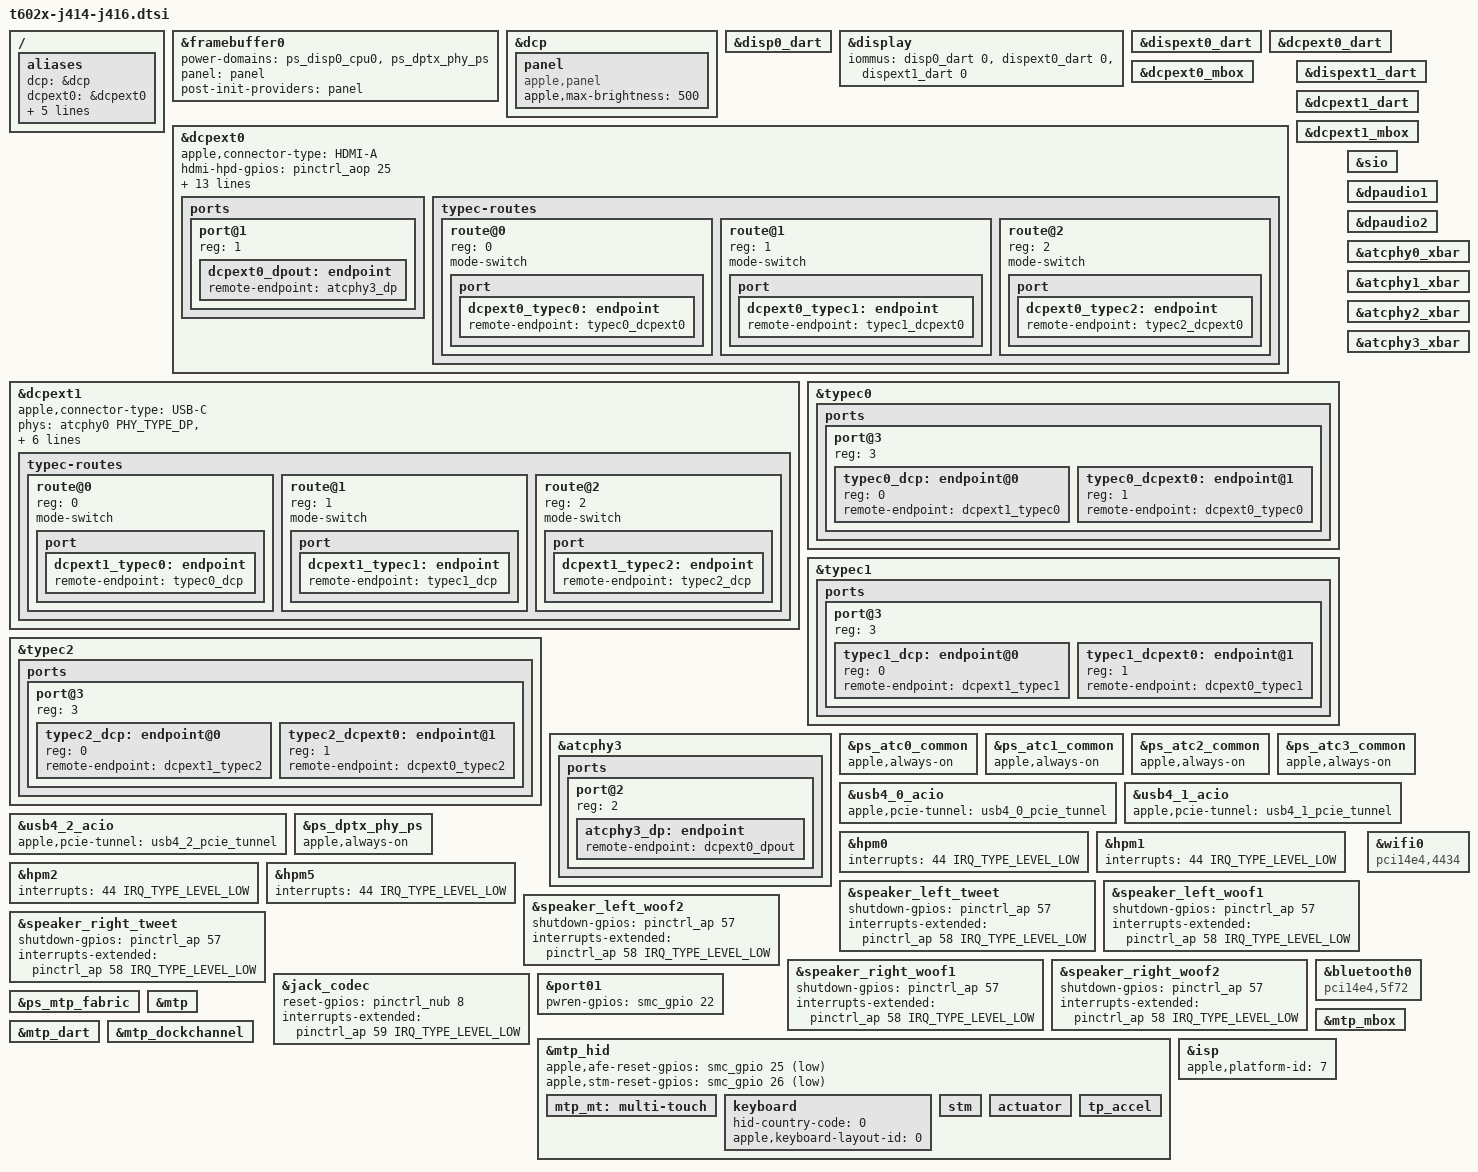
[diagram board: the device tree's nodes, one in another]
// SPDX-License-Identifier: GPL-2.0+ OR MIT
/*
 * MacBook Pro (14/16-inch, 2022)
 *
 * This file contains the parts common to J414 and J416 devices with both t6020 and t6021.
 *
 * target-type: J414s / J414c / J416s / J416c
 *
 * Copyright The Asahi Linux Contributors
 */

/*
 * These models are essentially identical to the previous generation, other than
 * the GPIO indices.
 */

#define NO_SPI_TRACKPAD
#include "t600x-j314-j316.dtsi"

/ {
	aliases {
		dcp = &dcp;
		dcpext0 = &dcpext0;
		dcpext1 = &dcpext1;
		disp0 = &display;
		disp0_piodma = &disp0_piodma;
		keyboard = &keyboard;
		sio = &sio;
	};
};

&framebuffer0 {
	power-domains = <&ps_disp0_cpu0>, <&ps_dptx_phy_ps>;
	panel = <&panel>;
	post-init-providers = <&panel>;
};

&dcp {
	panel: panel {
		compatible = "apple,panel";
		apple,max-brightness = <500>;
	};
};

&disp0_dart {
	status = "okay";
};

&display {
	iommus = <&disp0_dart 0>, <&dispext0_dart 0>, <&dispext1_dart 0>;
};

&dispext0_dart {
	status = "okay";
};

&dcpext0_dart {
	status = "okay";
};

&dcpext0_mbox {
	status = "okay";
};

&dcpext0 {
	status = "okay";
	apple,connector-type = "HDMI-A";
	hdmi-hpd-gpios = <&pinctrl_aop 25 GPIO_ACTIVE_HIGH>;
	hdmi-pwren-gpios = <&smc_gpio 23 GPIO_ACTIVE_HIGH>;
	dp2hdmi-pwren-gpios = <&smc_gpio 6 GPIO_ACTIVE_HIGH>;
	phys = <&atcphy3 PHY_TYPE_DP>, <&atcphy0 PHY_TYPE_DP>,
	       <&atcphy1 PHY_TYPE_DP>, <&atcphy2 PHY_TYPE_DP>;
	phy-names = "dp-phy", "typec0", "typec1", "typec2";
	mux-controls = <&atcphy3_xbar 0>, <&atcphy0_xbar 0>,
		       <&atcphy1_xbar 0>, <&atcphy2_xbar 0>;
	mux-control-names = "dp-xbar", "typec0", "typec1", "typec2";
	mux-index = <0>;
	apple,dptx-phy = <3>;
	apple,typec-mux-indices = <0 0 0>;
	apple,typec-dptx-phys = <0 1 2>;

	ports {
		#address-cells = <1>;
		#size-cells = <0>;

		port@1 {
			reg = <1>;
			dcpext0_dpout: endpoint {
				remote-endpoint = <&atcphy3_dp>;
			};
		};
	};

	typec-routes {
		#address-cells = <1>;
		#size-cells = <0>;

		route@0 {
			reg = <0>;
			mode-switch;

			port {
				dcpext0_typec0: endpoint {
					remote-endpoint = <&typec0_dcpext0>;
				};
			};
		};

		route@1 {
			reg = <1>;
			mode-switch;

			port {
				dcpext0_typec1: endpoint {
					remote-endpoint = <&typec1_dcpext0>;
				};
			};
		};

		route@2 {
			reg = <2>;
			mode-switch;

			port {
				dcpext0_typec2: endpoint {
					remote-endpoint = <&typec2_dcpext0>;
				};
			};
		};
	};
};

&dispext1_dart {
	status = "okay";
};

&dcpext1_dart {
	status = "okay";
};

&dcpext1_mbox {
	status = "okay";
};

&dcpext1 {
	/delete-property/ mux-index;
	status = "okay";
	apple,connector-type = "USB-C";
	phys = <&atcphy0 PHY_TYPE_DP>, <&atcphy1 PHY_TYPE_DP>,
	       <&atcphy2 PHY_TYPE_DP>;
	phy-names = "typec0", "typec1", "typec2";
	mux-controls = <&atcphy0_xbar 0>, <&atcphy1_xbar 0>,
		       <&atcphy2_xbar 0>;
	mux-control-names = "typec0", "typec1", "typec2";
	apple,typec-mux-indices = <2 2 2>;
	apple,typec-dptx-phys = <0 1 2>;

	typec-routes {
		#address-cells = <1>;
		#size-cells = <0>;

		route@0 {
			reg = <0>;
			mode-switch;

			port {
				dcpext1_typec0: endpoint {
					remote-endpoint = <&typec0_dcp>;
				};
			};
		};

		route@1 {
			reg = <1>;
			mode-switch;

			port {
				dcpext1_typec1: endpoint {
					remote-endpoint = <&typec1_dcp>;
				};
			};
		};

		route@2 {
			reg = <2>;
			mode-switch;

			port {
				dcpext1_typec2: endpoint {
					remote-endpoint = <&typec2_dcp>;
				};
			};
		};
	};
};

&typec0 {
	ports {
		port@3 {
			reg = <3>;
			#address-cells = <1>;
			#size-cells = <0>;

			typec0_dcp: endpoint@0 {
				reg = <0>;
				remote-endpoint = <&dcpext1_typec0>;
			};

			typec0_dcpext0: endpoint@1 {
				reg = <1>;
				remote-endpoint = <&dcpext0_typec0>;
			};
		};
	};
};

&typec1 {
	/delete-property/ displayport;
	ports {
		port@3 {
			reg = <3>;
			#address-cells = <1>;
			#size-cells = <0>;

			typec1_dcp: endpoint@0 {
				reg = <0>;
				remote-endpoint = <&dcpext1_typec1>;
			};

			typec1_dcpext0: endpoint@1 {
				reg = <1>;
				remote-endpoint = <&dcpext0_typec1>;
			};
		};
	};
};

&typec2 {
	ports {
		port@3 {
			reg = <3>;
			#address-cells = <1>;
			#size-cells = <0>;

			typec2_dcp: endpoint@0 {
				reg = <0>;
				remote-endpoint = <&dcpext1_typec2>;
			};

			typec2_dcpext0: endpoint@1 {
				reg = <1>;
				remote-endpoint = <&dcpext0_typec2>;
			};
		};
	};
};

&sio {
	status = "okay";
};

&dpaudio1 {
	status = "okay";
};

&dpaudio2 {
	status = "okay";
};

&atcphy0_xbar {
	status = "okay";
};

&atcphy1_xbar {
	status = "okay";
};

&atcphy2_xbar {
	status = "okay";
};

&atcphy3_xbar {
	status = "okay";
};

&atcphy3 {
	status = "okay";

	ports {
		#address-cells = <1>;
		#size-cells = <0>;

		port@2 {
			reg = <2>;
			atcphy3_dp: endpoint {
				remote-endpoint = <&dcpext0_dpout>;
			};
		};
	};
};

&ps_atc0_common {
	apple,always-on;
};

&ps_atc1_common {
	apple,always-on;
};

&ps_atc2_common {
	apple,always-on;
};

&ps_atc3_common {
	apple,always-on;
};

&usb4_0_acio {
	apple,pcie-tunnel = <&usb4_0_pcie_tunnel>;
};

&usb4_1_acio {
	apple,pcie-tunnel = <&usb4_1_pcie_tunnel>;
};

&usb4_2_acio {
	apple,pcie-tunnel = <&usb4_2_pcie_tunnel>;
};

/* Keep dptx_phy_ps on until DCP can sequence it during display bring-up. */
&ps_dptx_phy_ps {
	apple,always-on;
};

&dcpext0 {
	/*  HDMI HPD gpio, used as interrupt*/
	hdmi-hpd-gpios = <&pinctrl_aop 25 GPIO_ACTIVE_HIGH>;
};

&hpm0 {
	interrupts = <44 IRQ_TYPE_LEVEL_LOW>;
};

&hpm1 {
	interrupts = <44 IRQ_TYPE_LEVEL_LOW>;
};

&hpm2 {
	interrupts = <44 IRQ_TYPE_LEVEL_LOW>;
};

&hpm5 {
	interrupts = <44 IRQ_TYPE_LEVEL_LOW>;
};

&speaker_left_tweet {
	shutdown-gpios = <&pinctrl_ap 57 GPIO_ACTIVE_HIGH>;
	interrupts-extended = <&pinctrl_ap 58 IRQ_TYPE_LEVEL_LOW>;
};

&speaker_left_woof1 {
	shutdown-gpios = <&pinctrl_ap 57 GPIO_ACTIVE_HIGH>;
	interrupts-extended = <&pinctrl_ap 58 IRQ_TYPE_LEVEL_LOW>;
};

&speaker_left_woof2 {
	shutdown-gpios = <&pinctrl_ap 57 GPIO_ACTIVE_HIGH>;
	interrupts-extended = <&pinctrl_ap 58 IRQ_TYPE_LEVEL_LOW>;
};

&speaker_right_tweet {
	shutdown-gpios = <&pinctrl_ap 57 GPIO_ACTIVE_HIGH>;
	interrupts-extended = <&pinctrl_ap 58 IRQ_TYPE_LEVEL_LOW>;
};

&speaker_right_woof1 {
	shutdown-gpios = <&pinctrl_ap 57 GPIO_ACTIVE_HIGH>;
	interrupts-extended = <&pinctrl_ap 58 IRQ_TYPE_LEVEL_LOW>;
};

&speaker_right_woof2 {
	shutdown-gpios = <&pinctrl_ap 57 GPIO_ACTIVE_HIGH>;
	interrupts-extended = <&pinctrl_ap 58 IRQ_TYPE_LEVEL_LOW>;
};

&jack_codec {
	reset-gpios = <&pinctrl_nub 8 GPIO_ACTIVE_HIGH>;
	interrupts-extended = <&pinctrl_ap 59 IRQ_TYPE_LEVEL_LOW>;
};

&wifi0 {
	compatible = "pci14e4,4434";
};

&bluetooth0 {
	compatible = "pci14e4,5f72";
};

&port01 {
	pwren-gpios = <&smc_gpio 22 GPIO_ACTIVE_HIGH>;
};

&ps_mtp_fabric {
	status = "okay";
};

&mtp {
	status = "okay";
};

&mtp_mbox {
	status = "okay";
};

&mtp_dart {
	status = "okay";
};

&mtp_dockchannel {
	status = "okay";
};

&mtp_hid {
	apple,afe-reset-gpios = <&smc_gpio 25 GPIO_ACTIVE_LOW>;
	apple,stm-reset-gpios = <&smc_gpio 26 GPIO_ACTIVE_LOW>;

	mtp_mt: multi-touch {
	};

	keyboard: keyboard {
		hid-country-code = <0>;
		apple,keyboard-layout-id = <0>;
	};

	stm {
	};

	actuator {
	};

	tp_accel {
	};
};

&isp {
	apple,platform-id = <7>;
	/delete-node/ sensor-presets; /* Override j31[46] below */
};

#include "isp-imx558-cfg0.dtsi"
